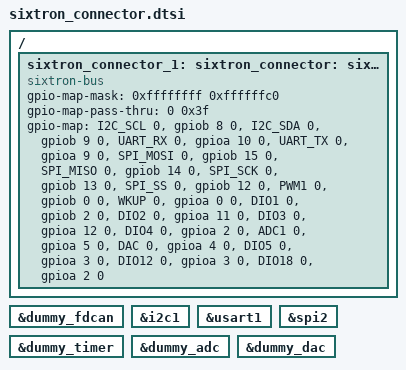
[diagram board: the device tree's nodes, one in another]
/*
 * Copyright (c) 2025 CATIE
 * SPDX-License-Identifier: Apache-2.0
 */

#include <zephyr/dt-bindings/gpio/sixtron-header.h>

/ {
    sixtron_connector_1: sixtron-connector-1 {
        compatible = "sixtron-bus";
        #gpio-cells = <2>;
        gpio-map-mask = <0xffffffff 0xffffffc0>;
        gpio-map-pass-thru = <0 0x3f>;
        gpio-map = <I2C_SCL 0 &gpiob 8 0>,
                   <I2C_SDA 0 &gpiob 9 0>,
                   <UART_RX 0 &gpioa 10 0>,
                   <UART_TX 0 &gpioa 9 0>,
                   <SPI_MOSI 0 &gpiob 15 0>,
                   <SPI_MISO 0 &gpiob 14 0>,
                   <SPI_SCK 0 &gpiob 13 0>,
                   <SPI_SS 0 &gpiob 12 0>,
                   <PWM1 0 &gpiob 0 0>,
                   <WKUP 0 &gpioa 0 0>,
                   <DIO1 0 &gpiob 2 0>,
                   <DIO2 0 &gpioa 11 0>,
                   <DIO3 0 &gpioa 12 0>,
                   <DIO4 0 &gpioa 2 0>,
                   <ADC1 0 &gpioa 5 0>,
                   <DAC 0 &gpioa 4 0>,
                   <DIO5 0 &gpioa 3 0>,
                   <DIO12 0 &gpioa 3 0>,
                   <DIO18 0 &gpioa 2 0>;
    };
};

sixtron_connector_1_can: &dummy_fdcan {};
sixtron_connector_1_i2c: &i2c1 {};
sixtron_connector_1_uart: &usart1 {};
sixtron_connector_1_spi: &spi2 {};
sixtron_connector_1_pwm: &dummy_timer {};
sixtron_connector_1_adc: &dummy_adc {};
sixtron_connector_1_dac: &dummy_dac {};

sixtron_can: &sixtron_connector_1_can {};
sixtron_i2c: &sixtron_connector_1_i2c {};
sixtron_uart: &sixtron_connector_1_uart {};
sixtron_spi: &sixtron_connector_1_spi {};
sixtron_pwm: &sixtron_connector_1_pwm {};
sixtron_adc: &sixtron_connector_1_adc {};
sixtron_dac: &sixtron_connector_1_dac {};

sixtron_connector: &sixtron_connector_1 {};
